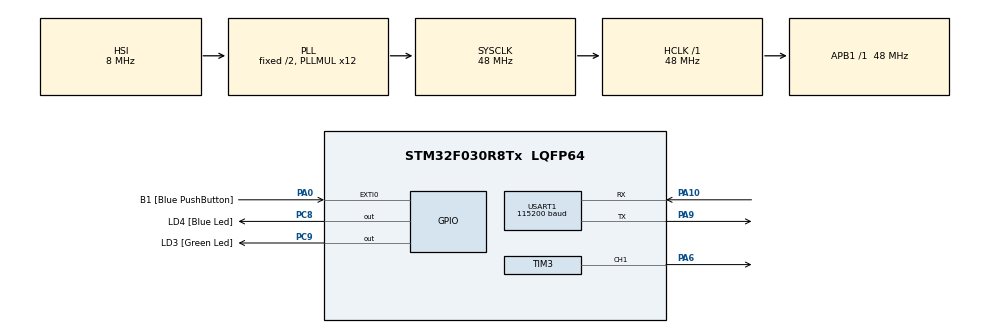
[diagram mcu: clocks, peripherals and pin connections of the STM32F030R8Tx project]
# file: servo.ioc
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Mcu.Family=STM32F0
Mcu.Name=STM32F030R8Tx
Mcu.Package=LQFP64
NVIC.TIM3_IRQn=true\:0\:0\:false\:false\:true\:true\:true
NVIC.TIM6_IRQn=true\:0\:0\:false\:false\:true\:true\:true
NVIC.USART1_IRQn=true\:0\:0\:false\:false\:true\:true\:true
PA0.GPIO_Label=B1 [Blue PushButton]
PA0.GPIO_ModeDefaultEXTI=GPIO_MODE_EVT_RISING
PA0.Signal=GPXTI0
PA10.Mode=Asynchronous
PA10.Signal=USART1_RX
PA13.GPIO_Label=SWDIO
PA13.Signal=SYS_SWDIO
PA14.GPIO_Label=SWCLK
PA14.Signal=SYS_SWCLK
PA6.Signal=S_TIM3_CH1
PA9.Mode=Asynchronous
PA9.Signal=USART1_TX
PC8.GPIO_Label=LD4 [Blue Led]
PC8.Signal=GPIO_Output
PC9.GPIO_Label=LD3 [Green Led]
PC9.Signal=GPIO_Output
ProjectManager.HeapSize=0x200
ProjectManager.StackSize=0x400
ProjectManager.TargetToolchain=TrueSTUDIO
RCC.AHBFreq_Value=48000000
RCC.APB1Freq_Value=48000000
RCC.APB1TimFreq_Value=48000000
RCC.HCLKFreq_Value=48000000
RCC.PLLMUL=RCC_PLL_MUL12
RCC.SYSCLKFreq_VALUE=48000000
RCC.SYSCLKSource=RCC_SYSCLKSOURCE_PLLCLK
SH.S_TIM3_CH1.0=TIM3_CH1,PWM Generation1 CH1
TIM3.AutoReloadPreload=TIM_AUTORELOAD_PRELOAD_ENABLE
TIM3.Channel-PWM\ Generation1\ CH1=TIM_CHANNEL_1
TIM3.CounterMode=TIM_COUNTERMODE_UP
TIM3.Period=200
TIM3.Prescaler=4800
TIM3.Pulse-PWM\ Generation1\ CH1=15
TIM6.AutoReloadPreload=TIM_AUTORELOAD_PRELOAD_ENABLE
TIM6.Period=32
TIM6.Prescaler=4800
USART1.BaudRate=115200
USART1.VirtualMode-Asynchronous=VM_ASYNC
VP_TIM6_VS_ClockSourceINT.Mode=Enable_Timer
board=32F0308DISCOVERY

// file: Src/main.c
/* USER CODE BEGIN Header */
/**
  ******************************************************************************
  * @file           : main.c
  * @brief          : Main program body
  ******************************************************************************
  * @attention
  *
  * <h2><center>&copy; Copyright (c) 2019 STMicroelectronics.
  * All rights reserved.</center></h2>
  *
  * This software component is licensed by ST under BSD 3-Clause license,
  * the "License"; You may not use this file except in compliance with the
  * License. You may obtain a copy of the License at:
  *                        opensource.org/licenses/BSD-3-Clause
  *
  ******************************************************************************
  */
/* USER CODE END Header */

#include "main.h"
#include "tim.h"
#include "usart.h"
#include "gpio.h"

void SystemClock_Config(void);

/* USER CODE BEGIN 0 */

uint16_t duty_cycle = 7;
uint16_t seconds_counter = 50 ;
void HAL_TIM_PeriodElapsedCallback(TIM_HandleTypeDef *htim)
{
	if (htim->Instance == TIM3) {

		if (seconds_counter) seconds_counter--;
		if (seconds_counter == 0) {
			seconds_counter = 50;
			if (duty_cycle >20 ){
				duty_cycle =7;
			}else{
				duty_cycle ++;
			}
		}
		htim->Instance->CCR1 = duty_cycle;
		__HAL_TIM_CLEAR_FLAG(htim,TIM_FLAG_UPDATE);
	}
}

/* USER CODE END 0 */

int main(void)
{

  /* MCU Configuration--------------------------------------------------------*/

  /* Reset of all peripherals, Initializes the Flash interface and the Systick. */
  HAL_Init();

  /* Configure the system clock */
  SystemClock_Config();

  /* Initialize all configured peripherals */
  MX_GPIO_Init();
  MX_TIM3_Init();
  MX_USART1_UART_Init();
  MX_TIM6_Init();

  /* Infinite loop */
  while (1)
  {

  }
}

void SystemClock_Config(void)
{
  RCC_OscInitTypeDef RCC_OscInitStruct = {0};
  RCC_ClkInitTypeDef RCC_ClkInitStruct = {0};
  RCC_PeriphCLKInitTypeDef PeriphClkInit = {0};

  /** Initializes the CPU, AHB and APB busses clocks
  */
  RCC_OscInitStruct.OscillatorType = RCC_OSCILLATORTYPE_HSI;
  RCC_OscInitStruct.HSIState = RCC_HSI_ON;
  RCC_OscInitStruct.HSICalibrationValue = RCC_HSICALIBRATION_DEFAULT;
  RCC_OscInitStruct.PLL.PLLState = RCC_PLL_ON;
  RCC_OscInitStruct.PLL.PLLSource = RCC_PLLSOURCE_HSI;
  RCC_OscInitStruct.PLL.PLLMUL = RCC_PLL_MUL12;
  RCC_OscInitStruct.PLL.PREDIV = RCC_PREDIV_DIV1;
  if (HAL_RCC_OscConfig(&RCC_OscInitStruct) != HAL_OK)
  {
    Error_Handler();
  }
  /** Initializes the CPU, AHB and APB busses clocks
  */
  RCC_ClkInitStruct.ClockType = RCC_CLOCKTYPE_HCLK|RCC_CLOCKTYPE_SYSCLK
                              |RCC_CLOCKTYPE_PCLK1;
  RCC_ClkInitStruct.SYSCLKSource = RCC_SYSCLKSOURCE_PLLCLK;
  RCC_ClkInitStruct.AHBCLKDivider = RCC_SYSCLK_DIV1;
  RCC_ClkInitStruct.APB1CLKDivider = RCC_HCLK_DIV1;

  if (HAL_RCC_ClockConfig(&RCC_ClkInitStruct, FLASH_LATENCY_1) != HAL_OK)
  {
    Error_Handler();
  }
  PeriphClkInit.PeriphClockSelection = RCC_PERIPHCLK_USART1;
  PeriphClkInit.Usart1ClockSelection = RCC_USART1CLKSOURCE_PCLK1;
  if (HAL_RCCEx_PeriphCLKConfig(&PeriphClkInit) != HAL_OK)
  {
    Error_Handler();
  }
}

void Error_Handler(void)
{
}

/************************ (C) COPYRIGHT STMicroelectronics *****END OF FILE****/
